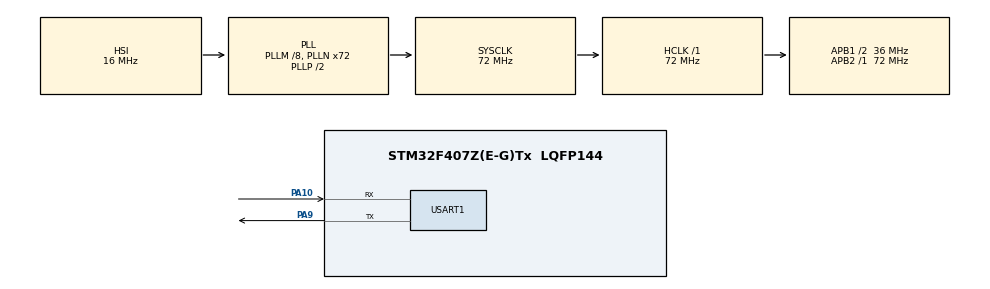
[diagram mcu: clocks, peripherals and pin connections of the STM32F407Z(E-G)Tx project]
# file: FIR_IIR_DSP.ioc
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Mcu.Family=STM32F4
Mcu.Name=STM32F407Z(E-G)Tx
Mcu.Package=LQFP144
NVIC.PriorityGroup=NVIC_PRIORITYGROUP_4
PA10.Mode=Asynchronous
PA10.Signal=USART1_RX
PA13.Mode=Serial_Wire
PA13.Signal=SYS_JTMS-SWDIO
PA14.Mode=Serial_Wire
PA14.Signal=SYS_JTCK-SWCLK
PA9.Mode=Asynchronous
PA9.Signal=USART1_TX
PC14-OSC32_IN.Mode=LSE-External-Oscillator
PC14-OSC32_IN.Signal=RCC_OSC32_IN
PC15-OSC32_OUT.Mode=LSE-External-Oscillator
PC15-OSC32_OUT.Signal=RCC_OSC32_OUT
PH0-OSC_IN.Mode=HSE-External-Oscillator
PH0-OSC_IN.Signal=RCC_OSC_IN
PH1-OSC_OUT.Mode=HSE-External-Oscillator
PH1-OSC_OUT.Signal=RCC_OSC_OUT
ProjectManager.HeapSize=0x200
ProjectManager.StackSize=0x400
ProjectManager.TargetToolchain=MDK-ARM V5.32
RCC.48MHZClocksFreq_Value=36000000
RCC.AHBFreq_Value=72000000
RCC.APB1CLKDivider=RCC_HCLK_DIV2
RCC.APB1Freq_Value=36000000
RCC.APB1TimFreq_Value=72000000
RCC.APB2Freq_Value=72000000
RCC.APB2TimFreq_Value=72000000
RCC.CortexFreq_Value=72000000
RCC.HCLKFreq_Value=72000000
RCC.HSE_VALUE=25000000
RCC.HSI_VALUE=16000000
RCC.PLLM=8
RCC.PLLN=72
RCC.SYSCLKFreq_VALUE=72000000
RCC.SYSCLKSource=RCC_SYSCLKSOURCE_PLLCLK
RCC.VCOOutputFreq_Value=144000000
USART1.VirtualMode=VM_ASYNC
board=custom

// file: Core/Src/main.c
/* USER CODE BEGIN Header */
/**
  ******************************************************************************
  * @file           : main.c
  * @brief          : Main program body
  ******************************************************************************
  * @attention
  *
  * Copyright (c) 2024 STMicroelectronics.
  * All rights reserved.
  *
  * This software is licensed under terms that can be found in the LICENSE file
  * in the root directory of this software component.
  * If no LICENSE file comes with this software, it is provided AS-IS.
  *
  ******************************************************************************
  */
/* USER CODE END Header */
#include "main.h"
#include "usart.h"
#include "gpio.h"

/* USER CODE BEGIN Includes */
#include <stdio.h>
#include "fir_coeffs.h"
#include "arm_math.h"
#include "arm_const_structs.h"
/* USER CODE END Includes */

/* USER CODE BEGIN PD */
#define DATA_LEN 2024
/* USER CODE END PD */

/* USER CODE BEGIN PM */
int fputc(int ch,FILE *f)
{
    uint8_t temp[1]={ch};
    HAL_UART_Transmit(&huart1, temp, 1, 2);
	return ch;
}
/* USER CODE END PM */

/* USER CODE BEGIN PV */
float input_buffer[DATA_LEN];
float output_buffer[DATA_LEN];
float fir_state[DATA_LEN + FILTER_TAP_NUM - 1];
arm_fir_instance_f32 S;
/* USER CODE END PV */

void SystemClock_Config(void);

int main(void)
{

  /* MCU Configuration--------------------------------------------------------*/

  /* Reset of all peripherals, Initializes the Flash interface and the Systick. */
  HAL_Init();

  /* Configure the system clock */
  SystemClock_Config();

  /* Initialize all configured peripherals */
  MX_GPIO_Init();
  MX_USART1_UART_Init();

  /* Infinite loop */
  /* USER CODE BEGIN WHILE */
		int i = 0;
  for(i = 0; i < DATA_LEN; i++){
		input_buffer[i] = 5 * sin(200 * 3.14 / DATA_LEN * i) + sin(1400 * 3.14 / DATA_LEN *i);
	}

	arm_fir_init_f32(&S, FILTER_TAP_NUM, filter_taps, fir_state, DATA_LEN);

	arm_fir_f32(&S, input_buffer, output_buffer, DATA_LEN);
	printf("FIR 滤波\r\n");
	for(i = 0; i < DATA_LEN; i++){
		printf("%d :  %.2f\r\n",i,output_buffer[i]);
	}
	printf("-------------------------------------------------------------------------------------");
	printf("FIR 原始波形\r\n");
	printf("input_buffer[i] = 5 * sin(200 * 3.14 / DATA_LEN * i) + sin(1400 * 3.14 / DATA_LEN *i)");
	for(i = 0; i < DATA_LEN; i++){
		printf("%d :  %.2f\r\n",i,input_buffer[i]);
	}
  while (1)
  {
    /* USER CODE END WHILE */

  }
}

void SystemClock_Config(void)
{
  RCC_OscInitTypeDef RCC_OscInitStruct = {0};
  RCC_ClkInitTypeDef RCC_ClkInitStruct = {0};

  /** Configure the main internal regulator output voltage
  */
  __HAL_RCC_PWR_CLK_ENABLE();
  __HAL_PWR_VOLTAGESCALING_CONFIG(PWR_REGULATOR_VOLTAGE_SCALE1);

  /** Initializes the RCC Oscillators according to the specified parameters
  * in the RCC_OscInitTypeDef structure.
  */
  RCC_OscInitStruct.OscillatorType = RCC_OSCILLATORTYPE_HSI;
  RCC_OscInitStruct.HSIState = RCC_HSI_ON;
  RCC_OscInitStruct.HSICalibrationValue = RCC_HSICALIBRATION_DEFAULT;
  RCC_OscInitStruct.PLL.PLLState = RCC_PLL_ON;
  RCC_OscInitStruct.PLL.PLLSource = RCC_PLLSOURCE_HSI;
  RCC_OscInitStruct.PLL.PLLM = 8;
  RCC_OscInitStruct.PLL.PLLN = 72;
  RCC_OscInitStruct.PLL.PLLP = RCC_PLLP_DIV2;
  RCC_OscInitStruct.PLL.PLLQ = 4;
  if (HAL_RCC_OscConfig(&RCC_OscInitStruct) != HAL_OK)
  {
    Error_Handler();
  }

  /** Initializes the CPU, AHB and APB buses clocks
  */
  RCC_ClkInitStruct.ClockType = RCC_CLOCKTYPE_HCLK|RCC_CLOCKTYPE_SYSCLK
                              |RCC_CLOCKTYPE_PCLK1|RCC_CLOCKTYPE_PCLK2;
  RCC_ClkInitStruct.SYSCLKSource = RCC_SYSCLKSOURCE_PLLCLK;
  RCC_ClkInitStruct.AHBCLKDivider = RCC_SYSCLK_DIV1;
  RCC_ClkInitStruct.APB1CLKDivider = RCC_HCLK_DIV2;
  RCC_ClkInitStruct.APB2CLKDivider = RCC_HCLK_DIV1;

  if (HAL_RCC_ClockConfig(&RCC_ClkInitStruct, FLASH_LATENCY_2) != HAL_OK)
  {
    Error_Handler();
  }
}

void Error_Handler(void)
{
  __disable_irq();
  while (1)
  {
  }
}
